# N32H7xx register map
Vendor: Nationstech Ltd.; File version: 1.0
CPU: CM7 r1p1, little endian, MPU, FPU, 4 interrupt priority bits
Registers are 32-bit, read-write, reset 0x0 unless marked. A register's access mark holds for its fields unless they carry their own. Offsets are from the block's base; [hi:lo] are bit positions; {n}, {i} and the like mark numbered series.

## BTIM1 — Basic timer
Base 0x4000A000
Same registers: BTIM2 0x4000A400, BTIM3 0x40010800, BTIM4 0x40010C00
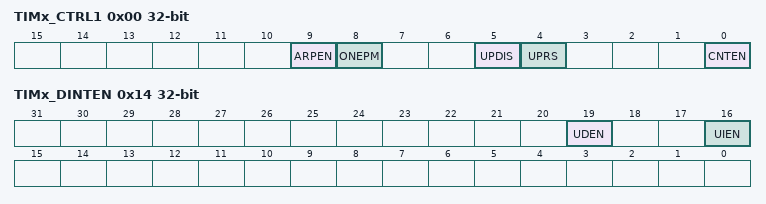
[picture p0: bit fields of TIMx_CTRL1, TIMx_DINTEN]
0x00 TIMx_CTRL1
  [9] ARPEN, [8] ONEPM, [5] UPDIS, [4] UPRS, [0] CNTEN
0x04 TIMx_CTRL2
  [15:12] MMSEL
0x08 TIMx_STS
  [16] UDITF
0x0C TIMx_EVTGEN wo
  [8] UDGN
0x14 TIMx_DINTEN
  [19] UDEN, [16] UIEN
0x40 TIMx_PSC
  [15:0] PSC
0x44 TIMx_AR reset 0xFFFFFFFF
0x48 TIMx_CNT

## LPTIM1 — Low Power Timer
Base 0x58001000
Same registers: LPTIM2 0x58001400, LPTIM3 0x58001800, LPTIM4 0x58001C00, LPTIM5 0x58005800
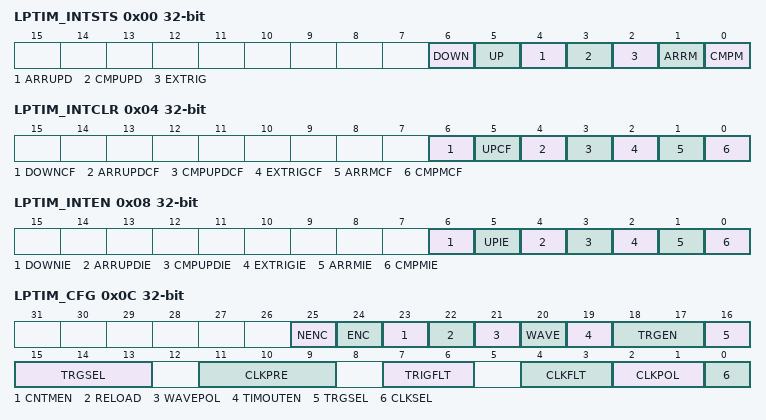
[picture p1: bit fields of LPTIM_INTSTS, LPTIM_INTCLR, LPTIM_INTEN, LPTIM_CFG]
0x00 LPTIM_INTSTS ro — LPTIM Interrupt and Status Register
  [6] DOWN — Change counter direction down
  [5] UP — Change counter direction up
  [4] ARRUPD — Auto-reload value updated to register
  [3] CMPUPD — Compare value updated to register
  [2] EXTRIG — External trigger valid event
  [1] ARRM — Auto-reload match
  [0] CMPM — Compare match
0x04 LPTIM_INTCLR wo — LPTIM Interrupt Clear Register
  [6] DOWNCF — Change counter direction down clear flag
  [5] UPCF — Change counter direction up clear flag
  [4] ARRUPDCF — Auto-reload value updated to register clear flag
  [3] CMPUPDCF — Compare value updated to register clear flag
  [2] EXTRIGCF — External trigger valid edge clear flag
  [1] ARRMCF — Auto-reload match clear flag
  [0] CMPMCF — Compare match clear flag
0x08 LPTIM_INTEN — LPTIM Interrupt Enable Register
  [6] DOWNIE — Change counter direction down interrupt enable bit
  [5] UPIE — Change counter direction up interrupt enable bit
  [4] ARRUPDIE — Auto-reload value updated to register interrupt enable bit
  [3] CMPUPDIE — Compare value updated to register interrupt enable bit
  [2] EXTRIGIE — External trigger valid edge interrupt enable bit
  [1] ARRMIE — Auto-reload match interrupt enable bit
  [0] CMPMIE — Compare match interrupt enable bit
0x0C LPTIM_CFG — LPTIM Configuration Register
  [25] NENC — Non-orthgonal mode enable
  [24] ENC — Encoder mode enable
  [23] CNTMEN — Counter mode enabled
  [22] RELOAD — Register update mode
  [21] WAVEPOL — Waveform shape polarity
  [20] WAVE — Waveform shape
  [19] TIMOUTEN — Timeout enable
  [18:17] TRGEN — Trigger enable and polatiry bit
  [16:13] TRGSEL — Tigger selctor
  [11:9] CLKPRE — Clock division factor bit
  [7:6] TRIGFLT — Configure the data filter trigger bit
  [4:3] CLKFLT — Ditital filter external clock input configuration
  [2:1] CLKPOL — Clock Polarity
  [0] CLKSEL — Clock selctor
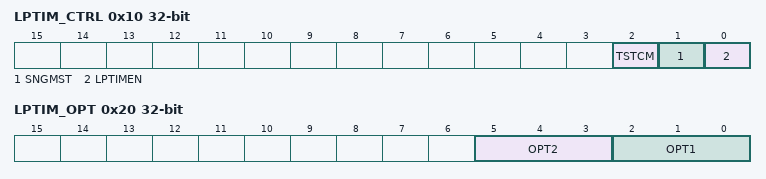
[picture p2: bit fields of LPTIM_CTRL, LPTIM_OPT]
0x10 LPTIM_CTRL — LPTIM Control Register
  [2] TSTCM — Timer start in Continuous mode
  [1] SNGMST — LPTIM start in Single pulse mode
  [0] LPTIMEN — LPTIM enable
0x14 LPTIM_CMP — LPTIM Compare Register
  [15:0] CMPVAL — Compare value
0x18 LPTIM_ARR reset 0x1 — LPTIM Auto-Reload Register
  [15:0] ARRVAL — Auto reload value
0x1C LPTIM_CNT ro — LPTIM Coutnter Register
  [15:0] CNTVAL — Counter value
0x20 LPTIM_OPT — LPTIM Option Register
  [5:3] OPT2 — LPTIM Input2 Connection selection bit
  [2:0] OPT1 — LPTIM Input1 Connection selection bit

## SHRTIM1_Master — Super high resolution timer: Master Timers
Base 0x400D8000
Same registers: SHRTIM2_Master 0x400D9000
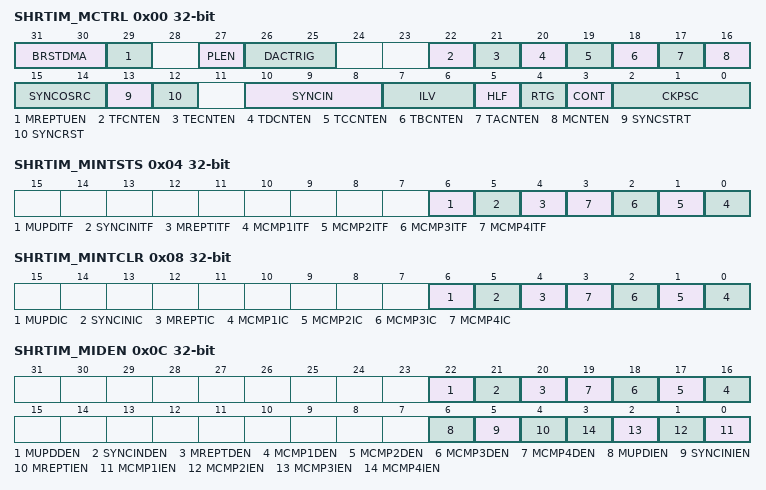
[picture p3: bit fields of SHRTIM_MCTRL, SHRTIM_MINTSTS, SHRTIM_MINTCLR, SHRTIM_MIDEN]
0x00 SHRTIM_MCTRL — SHRTIM configuration register for master timer
  [31:30] BRSTDMA, [29] MREPTUEN, [27] PLEN, [26:25] DACTRIG, [22] TFCNTEN, [21] TECNTEN, [20] TDCNTEN, [19] TCCNTEN, [18] TBCNTEN, [17] TACNTEN, [16] MCNTEN, [15:14] SYNCOSRC, [13] SYNCSTRT, [12] SYNCRST, [10:8] SYNCIN, [7:6] ILV, [5] HLF, [4] RTG, [3] CONT, [2:0] CKPSC
0x04 SHRTIM_MINTSTS ro — SHRTIM status register for master timer interrupt
  [6] MUPDITF, [5] SYNCINITF, [4] MREPTITF, [n-1] MCMP{n}ITF (n=1..4)
0x08 SHRTIM_MINTCLR wo — SHRTIM master timer interrupt clear register
  [6] MUPDIC, [5] SYNCINIC, [4] MREPTIC, [n-1] MCMP{n}IC (n=1..4)
0x0C SHRTIM_MIDEN — SHRTIM master timer interrupt and DMA request enable register
  [22] MUPDDEN, [21] SYNCINDEN, [20] MREPTDEN, [n+15] MCMP{n}DEN (n=1..4), [6] MUPDIEN, [5] SYNCINIEN, [4] MREPTIEN, [n-1] MCMP{n}IEN (n=1..4)
0x10 SHRTIM_MCNT — SHRTIM master timer counter register
  [15:0] MCOUNT
0x14 SHRTIM_MPRD reset 0xFFDF — SHRTIM master timer period register
  [15:0] MPRD
0x18 SHRTIM_MREPT — SHRTIM master timer repetition register
  [7:0] MREPT
0x1C SHRTIM_MCMP1DAT — SHRTIM master timer compare 1 register
  [15:0] MCMP1DAT
{0x1C+4i} SHRTIM_MCMP{i}DAT (i=2..4) — SHRTIM master timer compare {i} register
  [15:0] MCMP{i}DAT
0x30 SHRTIM_SYNCOUT — SYNOUT configure register
  [1:0] SYNCOUTPUS
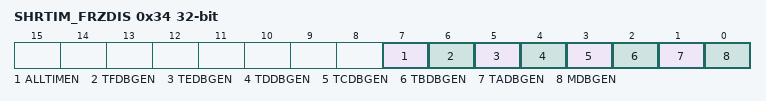
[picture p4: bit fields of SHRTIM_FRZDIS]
0x34 SHRTIM_FRZDIS — Timer behavior during CPU freeze
  [7] ALLTIMEN, [6] TFDBGEN, [5] TEDBGEN, [4] TDDBGEN, [3] TCDBGEN, [2] TBDBGEN, [1] TADBGEN, [0] MDBGEN
